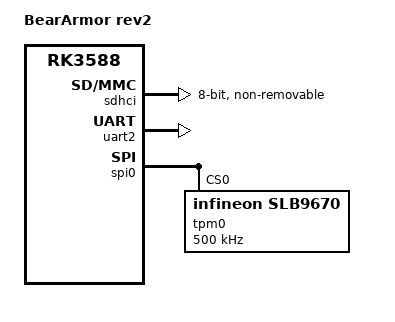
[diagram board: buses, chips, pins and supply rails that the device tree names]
/dts-v1/;
#include "rk3588s.dtsi"

/ {
	model = "BearArmor rev2";
	compatible = "rockchip,rk3588";

	reserved-memory {
		#address-cells = <2>;
		#size-cells = <2>;
		ranges;

		tpm_event_log: tpm-event-log@28000000 {
			reg = <0x0 0x28000000 0x0 0x10000>; /* 640 MiB base, 64 KiB size */
			no-map;
		};
	};

	aliases {
		mmc0 = &sdhci;
	};

	chosen {
		stdout-path = "serial2:1500000n8";
	};
};

&sdhci {
	bus-width = <8>;
	cap-mmc-highspeed;
	mmc-hs200-1_8v;
	no-sd;
	no-sdio;
	non-removable;
	status = "okay";
};

&uart2 {
	pinctrl-0 = <&uart2m0_xfer>;
	status = "okay";
};

&spi0 {
	num-cs = <1>;
	pinctrl-0 = <&spi0m3_cs0 &spi0m3_pins>;
	pinctrl-names = "default";
	status = "okay";

	tpm0: tpm@0 {
		compatible = "infineon,slb9670", "tis,tpm2-spi", "tcg,tpm_tis-spi";
		memory-region = <&tpm_event_log>;
		reg = <0>;
		spi-max-frequency = <500000>;
		status = "okay";
	};
};

&spi0m3_pins {
	rockchip,pins =
		/* spi0_clk_m3 */
		<3 RK_PD3 8 &pcfg_pull_up_drv_level_6>,
		/* spi0_miso_m3 */
		<3 RK_PD1 8 &pcfg_pull_up_drv_level_6>,
		/* spi0_mosi_m3 */
		<3 RK_PD2 8 &pcfg_pull_up_drv_level_6>;
};

&spi0m3_cs0 {
	rockchip,pins =
		/* spi0_cs0_m3 */
		<3 RK_PD4 8 &pcfg_pull_up_drv_level_6>;
};
